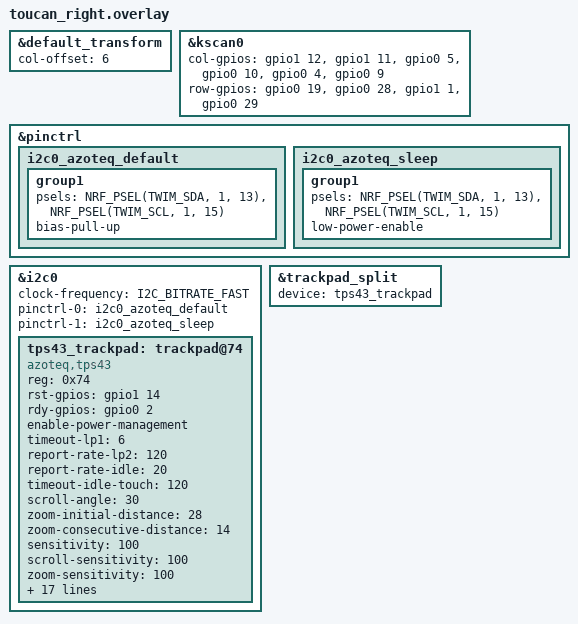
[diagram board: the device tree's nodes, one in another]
#include "toucan.dtsi"

&default_transform {
    col-offset = <6>;
};

&kscan0 {
    col-gpios
    = <&gpio1 12 GPIO_ACTIVE_HIGH>
    , <&gpio1 11 GPIO_ACTIVE_HIGH>
    , <&gpio0 5 GPIO_ACTIVE_HIGH>
    , <&gpio0 10 GPIO_ACTIVE_HIGH>
    , <&gpio0 4 GPIO_ACTIVE_HIGH>
    , <&gpio0 9 GPIO_ACTIVE_HIGH>
    ;

    row-gpios
    = <&gpio0 19 (GPIO_ACTIVE_HIGH | GPIO_PULL_DOWN)>
    , <&gpio0 28 (GPIO_ACTIVE_HIGH | GPIO_PULL_DOWN)>
    , <&gpio1 1 (GPIO_ACTIVE_HIGH | GPIO_PULL_DOWN)>
    , <&gpio0 29 (GPIO_ACTIVE_HIGH | GPIO_PULL_DOWN)>
    ;
};

&pinctrl {
    i2c0_azoteq_default: i2c0_azoteq_default {
        group1 {
            psels = <NRF_PSEL(TWIM_SDA, 1, 13)>,
                    <NRF_PSEL(TWIM_SCL, 1, 15)>;
            bias-pull-up;
        };
    };

    i2c0_azoteq_sleep: i2c0_azoteq_sleep {
        group1 {
            psels = <NRF_PSEL(TWIM_SDA, 1, 13)>,
                    <NRF_PSEL(TWIM_SCL, 1, 15)>;
            low-power-enable;
        };
    };
};

&i2c0 {
   status = "okay";
    clock-frequency = <I2C_BITRATE_FAST>;
    pinctrl-0 = <&i2c0_azoteq_default>;
    pinctrl-1 = <&i2c0_azoteq_sleep>;
    pinctrl-names = "default", "sleep";

    tps43_trackpad: trackpad@74 {
        compatible = "azoteq,tps43";
        reg = <0x74>;
        status = "okay";

        rst-gpios = <&gpio1 14 GPIO_ACTIVE_HIGH>;
        rdy-gpios = <&gpio0 2 GPIO_ACTIVE_HIGH>;

        enable-power-management;
        // idle-sleep; // provides maximal power savings but when ZMK is idle (i.e. you haven't used keyboard in 30secs) the touchpad will not work.  not recommended.
        timeout-lp1 = <6>; // 2min in LP1 (80ms rate) before LP2 deep sleep (was 3 = 60s) — snappier wake, small idle cost
        report-rate-lp2 = <120>; // 120ms wake cadence in LP2 (register unit is plain ms; was 160) — faster wake, slight idle cost
        report-rate-idle = <20>; // 20ms poll while pad-idle (preset 50): first touch after a pause feels instant
        timeout-idle-touch = <120>; // linger 2min in IDLE-TOUCH (50ms) after touch ends (preset 60s): back-to-back use stays hot
        scroll-angle = <30>;
        zoom-initial-distance = <28>; // explicit pinch gate: high enough scroll keeps priority for small two-finger motions; raise to 36 if scroll still hijacks
        zoom-consecutive-distance = <14>; // half of initial: once zooming, keep flowing
        sensitivity = <100>;
        scroll-sensitivity = <100>;
        zoom-sensitivity = <100>;
        precision-damp; // halve sub-4px cursor reports to kill slow-drag tremor; full speed returns on any >=6px report
        filter-settings=<0x0B>;
        hold-time = <320>;

        zoom;
        scroll;
        two-finger-tap;
        single-tap;
        press-and-hold;
        //swipes;
        three-finger-swipe;
        three-finger-swipe-throttle-ms = <1200>;
        switch-xy;
        //invert-scroll-y;
        invert-scroll-x;

        drag-continuation;
        drag-continuation-edge-buffer = <100>; // default 80 +25%: easier to catch, still edge-only
        drag-continuation-slide; // auto-slide at rest in the buffer: defaults 250 ms dwell / 12 px still
        drag-continuation-slide-speed = <800>;

        three-finger-tap; 
    };
};

&trackpad_split {
    device = <&tps43_trackpad>;
};
